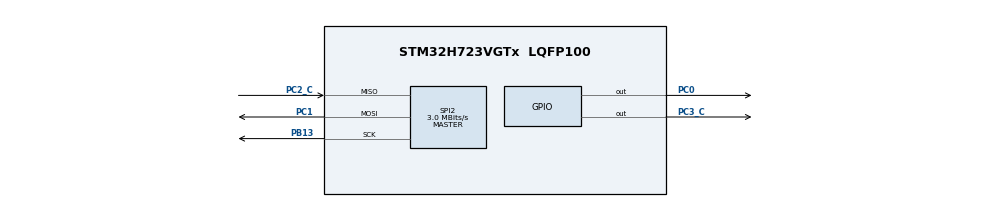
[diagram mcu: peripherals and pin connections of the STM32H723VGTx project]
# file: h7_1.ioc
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Mcu.Family=STM32H7
Mcu.Name=STM32H723VGTx
Mcu.Package=LQFP100
NVIC.PriorityGroup=NVIC_PRIORITYGROUP_4
NVIC.TIM6_DAC_IRQn=true\:0\:0\:false\:false\:true\:true\:true
PA13(JTMS/SWDIO).Mode=Serial_Wire
PA13(JTMS/SWDIO).Signal=DEBUG_JTMS-SWDIO
PA14(JTCK/SWCLK).Mode=Serial_Wire
PA14(JTCK/SWCLK).Signal=DEBUG_JTCK-SWCLK
PB13.Mode=Full_Duplex_Master
PB13.Signal=SPI2_SCK
PC0.GPIO_Speed=GPIO_SPEED_FREQ_MEDIUM
PC0.PinState=GPIO_PIN_SET
PC0.Signal=GPIO_Output
PC1.Mode=Full_Duplex_Master
PC1.Signal=SPI2_MOSI
PC2_C.Mode=Full_Duplex_Master
PC2_C.Signal=SPI2_MISO
PC3_C.GPIO_Speed=GPIO_SPEED_FREQ_MEDIUM
PC3_C.PinState=GPIO_PIN_SET
PC3_C.Signal=GPIO_Output
PH0-OSC_IN.Mode=HSE-External-Oscillator
PH0-OSC_IN.Signal=RCC_OSC_IN
PH1-OSC_OUT.Mode=HSE-External-Oscillator
PH1-OSC_OUT.Signal=RCC_OSC_OUT
ProjectManager.HeapSize=0x200
ProjectManager.StackSize=0x400
ProjectManager.TargetToolchain=MDK-ARM V5.32
RCC.ADCFreq_Value=48375000
RCC.APB1Freq_Value=32000000
RCC.APB2Freq_Value=32000000
RCC.APB3Freq_Value=32000000
RCC.APB4Freq_Value=32000000
RCC.CortexFreq_Value=64000000
RCC.D1PPRE=RCC_APB3_DIV2
RCC.D2PPRE1=RCC_APB1_DIV2
RCC.D2PPRE2=RCC_APB2_DIV2
RCC.D3PPRE=RCC_APB4_DIV2
RCC.DIVM1=2
RCC.DIVN1=16
RCC.DIVQ1=4
RCC.HCLKFreq_Value=64000000
RCC.HSE_VALUE=24000000
RCC.PLL2FRACN=0
RCC.PLL3FRACN=0
RCC.PLLFRACN=0
RCC.PLLSourceVirtual=RCC_PLLSOURCE_HSE
RCC.SYSCLKFreq_VALUE=64000000
RCC.USBFreq_Value=48000000
SPI2.BaudRatePrescaler=SPI_BAUDRATEPRESCALER_16
SPI2.CalculateBaudRate=3.0 MBits/s
SPI2.DataSize=SPI_DATASIZE_8BIT
SPI2.Direction=SPI_DIRECTION_2LINES
SPI2.Mode=SPI_MODE_MASTER
SPI2.VirtualType=VM_MASTER
TIM6.Period=999
TIM6.Prescaler=63
VP_TIM6_VS_ClockSourceINT.Mode=Enable_Timer
board=custom

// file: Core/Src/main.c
/* USER CODE BEGIN Header */
/**
  ******************************************************************************
  * @file           : main.c
  * @brief          : Main program body
  ******************************************************************************
  * @attention
  *
  * <h2><center>&copy; Copyright (c) 2026 STMicroelectronics.
  * All rights reserved.</center></h2>
  *
  * This software component is licensed by ST under BSD 3-Clause license,
  * the "License"; You may not use this file except in compliance with the
  * License. You may obtain a copy of the License at:
  *                        opensource.org/licenses/BSD-3-Clause
  *
  ******************************************************************************
  */
/* USER CODE END Header */
#include "main.h"
#include "spi.h"
#include "tim.h"
#include "gpio.h"

/* USER CODE BEGIN Includes */
#include "imu.h"

/* USER CODE END Includes */

void SystemClock_Config(void);

/* USER CODE BEGIN 0 */
uint8_t spi_tx[8] = {0xFF,0xFF,0xFF,0xFF,0xFF,0xFF,0xFF,0xFF};
uint8_t spi_rx[8];
HAL_StatusTypeDef spi_status;
/* USER CODE END 0 */

int main(void)
{

  /* MCU Configuration--------------------------------------------------------*/

  /* Reset of all peripherals, Initializes the Flash interface and the Systick. */
  HAL_Init();

  /* Configure the system clock */
  SystemClock_Config();

  /* Initialize all configured peripherals */
  MX_GPIO_Init();
  MX_TIM6_Init();
  MX_SPI2_Init();
  /* USER CODE BEGIN 2 */
BMI088_Gyro_Init();

  /* USER CODE END 2 */

  /* Infinite loop */
  /* USER CODE BEGIN WHILE */
  while (1)
  {
	  if (bmi088_init_ok != 0U)
	  {
		  BMI088_Gyro_Update();
		  HAL_Delay(1);
	  }
	  else
	  {
		  HAL_Delay(100);
		  BMI088_Gyro_Init();
	  }
    /* USER CODE END WHILE */

  }
}

void SystemClock_Config(void)
{
  RCC_OscInitTypeDef RCC_OscInitStruct = {0};
  RCC_ClkInitTypeDef RCC_ClkInitStruct = {0};

  /** Supply configuration update enable
  */
  HAL_PWREx_ConfigSupply(PWR_LDO_SUPPLY);
  /** Configure the main internal regulator output voltage
  */
  __HAL_PWR_VOLTAGESCALING_CONFIG(PWR_REGULATOR_VOLTAGE_SCALE3);

  while(!__HAL_PWR_GET_FLAG(PWR_FLAG_VOSRDY)) {}
  /** Initializes the RCC Oscillators according to the specified parameters
  * in the RCC_OscInitTypeDef structure.
  */
  RCC_OscInitStruct.OscillatorType = RCC_OSCILLATORTYPE_HSI|RCC_OSCILLATORTYPE_HSE;
  RCC_OscInitStruct.HSEState = RCC_HSE_ON;
  RCC_OscInitStruct.HSIState = RCC_HSI_DIV1;
  RCC_OscInitStruct.HSICalibrationValue = RCC_HSICALIBRATION_DEFAULT;
  RCC_OscInitStruct.PLL.PLLState = RCC_PLL_ON;
  RCC_OscInitStruct.PLL.PLLSource = RCC_PLLSOURCE_HSE;
  RCC_OscInitStruct.PLL.PLLM = 2;
  RCC_OscInitStruct.PLL.PLLN = 16;
  RCC_OscInitStruct.PLL.PLLP = 2;
  RCC_OscInitStruct.PLL.PLLQ = 4;
  RCC_OscInitStruct.PLL.PLLR = 2;
  RCC_OscInitStruct.PLL.PLLRGE = RCC_PLL1VCIRANGE_3;
  RCC_OscInitStruct.PLL.PLLVCOSEL = RCC_PLL1VCOWIDE;
  RCC_OscInitStruct.PLL.PLLFRACN = 0;
  if (HAL_RCC_OscConfig(&RCC_OscInitStruct) != HAL_OK)
  {
    Error_Handler();
  }
  /** Initializes the CPU, AHB and APB buses clocks
  */
  RCC_ClkInitStruct.ClockType = RCC_CLOCKTYPE_HCLK|RCC_CLOCKTYPE_SYSCLK
                              |RCC_CLOCKTYPE_PCLK1|RCC_CLOCKTYPE_PCLK2
                              |RCC_CLOCKTYPE_D3PCLK1|RCC_CLOCKTYPE_D1PCLK1;
  RCC_ClkInitStruct.SYSCLKSource = RCC_SYSCLKSOURCE_HSI;
  RCC_ClkInitStruct.SYSCLKDivider = RCC_SYSCLK_DIV1;
  RCC_ClkInitStruct.AHBCLKDivider = RCC_HCLK_DIV1;
  RCC_ClkInitStruct.APB3CLKDivider = RCC_APB3_DIV2;
  RCC_ClkInitStruct.APB1CLKDivider = RCC_APB1_DIV2;
  RCC_ClkInitStruct.APB2CLKDivider = RCC_APB2_DIV2;
  RCC_ClkInitStruct.APB4CLKDivider = RCC_APB4_DIV2;

  if (HAL_RCC_ClockConfig(&RCC_ClkInitStruct, FLASH_LATENCY_1) != HAL_OK)
  {
    Error_Handler();
  }
}

void Error_Handler(void)
{
  __disable_irq();
  while (1)
  {
  }
}

/************************ (C) COPYRIGHT STMicroelectronics *****END OF FILE****/
